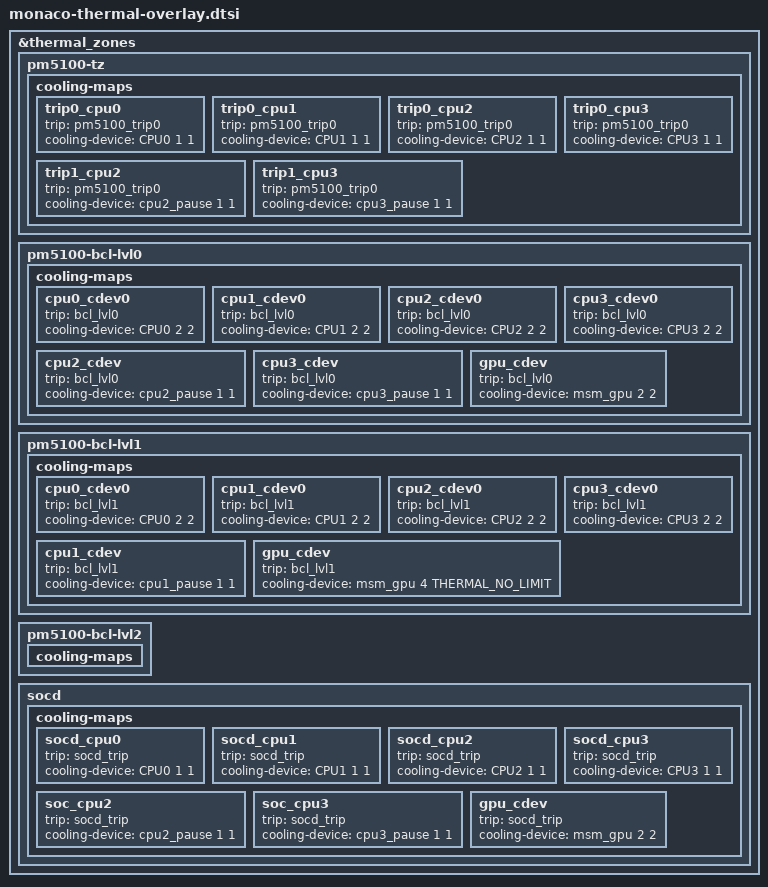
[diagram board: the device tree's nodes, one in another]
// SPDX-License-Identifier: BSD-3-Clause
/*
 * Copyright (c) 2024 Qualcomm Innovation Center, Inc. All rights reserved.
 */

#include <dt-bindings/thermal/thermal_qti.h>

&thermal_zones {
	pm5100-tz {
		cooling-maps {
			trip0_cpu0 {
				trip = <&pm5100_trip0>;
				cooling-device = <&CPU0 1 1>;
			};

			trip0_cpu1 {
				trip = <&pm5100_trip0>;
				cooling-device = <&CPU1 1 1>;
			};

			trip0_cpu2 {
				trip = <&pm5100_trip0>;
				cooling-device = <&CPU2 1 1>;
			};

			trip0_cpu3 {
				trip = <&pm5100_trip0>;
				cooling-device = <&CPU3 1 1>;
			};

			trip1_cpu2 {
				trip = <&pm5100_trip0>;
				cooling-device = <&cpu2_pause 1 1>;
			};

			trip1_cpu3 {
				trip = <&pm5100_trip0>;
				cooling-device = <&cpu3_pause 1 1>;
			};
		};
	};

	pm5100-bcl-lvl0 {
		cooling-maps {
			cpu0_cdev0 {
				trip = <&bcl_lvl0>;
				cooling-device = <&CPU0 2 2>;
			};

			cpu1_cdev0 {
				trip = <&bcl_lvl0>;
				cooling-device = <&CPU1 2 2>;
			};

			cpu2_cdev0 {
				trip = <&bcl_lvl0>;
				cooling-device = <&CPU2 2 2>;
			};

			cpu3_cdev0 {
				trip = <&bcl_lvl0>;
				cooling-device = <&CPU3 2 2>;
			};

			cpu2_cdev {
				trip = <&bcl_lvl0>;
				cooling-device = <&cpu2_pause 1 1>;
			};

			cpu3_cdev {
				trip = <&bcl_lvl0>;
				cooling-device = <&cpu3_pause 1 1>;
			};

			gpu_cdev {
				trip = <&bcl_lvl0>;
				cooling-device = <&msm_gpu 2 2>;
			};
		};
	};

	pm5100-bcl-lvl1 {
		cooling-maps {
			cpu0_cdev0 {
				trip = <&bcl_lvl1>;
				cooling-device = <&CPU0 2 2>;
			};

			cpu1_cdev0 {
				trip = <&bcl_lvl1>;
				cooling-device = <&CPU1 2 2>;
			};

			cpu2_cdev0 {
				trip = <&bcl_lvl1>;
				cooling-device = <&CPU2 2 2>;
			};

			cpu3_cdev0 {
				trip = <&bcl_lvl1>;
				cooling-device = <&CPU3 2 2>;
			};

			cpu1_cdev {
				trip = <&bcl_lvl1>;
				cooling-device = <&cpu1_pause 1 1>;
			};

			gpu_cdev {
				trip = <&bcl_lvl1>;
				cooling-device = <&msm_gpu 4 THERMAL_NO_LIMIT>;
			};
		};
	};

	pm5100-bcl-lvl2 {
		cooling-maps {
			/* Need to update once we get fine tuned data */
		};
	};

	socd {
		cooling-maps {
			socd_cpu0 {
				trip = <&socd_trip>;
				cooling-device = <&CPU0 1 1>;
			};

			socd_cpu1 {
				trip = <&socd_trip>;
				cooling-device = <&CPU1 1 1>;
			};

			socd_cpu2 {
				trip = <&socd_trip>;
				cooling-device = <&CPU2 1 1>;
			};

			socd_cpu3 {
				trip = <&socd_trip>;
				cooling-device = <&CPU3 1 1>;
			};

			soc_cpu2 {
				trip = <&socd_trip>;
				cooling-device = <&cpu2_pause 1 1>;
			};

			soc_cpu3 {
				trip = <&socd_trip>;
				cooling-device = <&cpu3_pause 1 1>;
			};

			gpu_cdev {
				trip = <&socd_trip>;
				cooling-device = <&msm_gpu 2 2>;
			};
		};
	};
};
